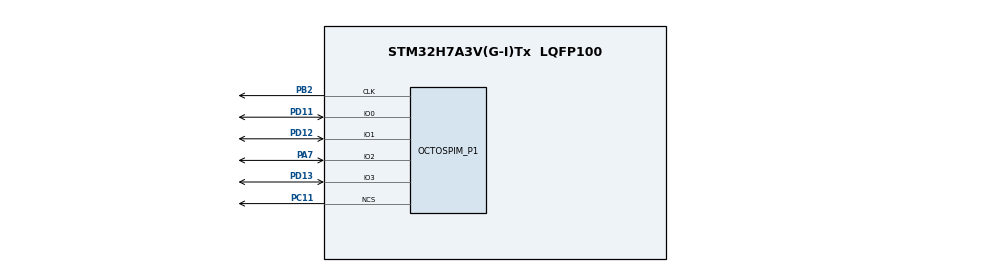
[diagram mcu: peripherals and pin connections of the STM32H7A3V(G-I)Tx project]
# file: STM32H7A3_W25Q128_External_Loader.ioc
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CORTEX_M7.AccessPermission_S-Cortex_Memory_Protection_Unit_Region1_Settings_S=MPU_REGION_FULL_ACCESS
CORTEX_M7.BaseAddress_S-Cortex_Memory_Protection_Unit_Region1_Settings_S=0x90000000
CORTEX_M7.Enable_S-Cortex_Memory_Protection_Unit_Region1_Settings_S=MPU_REGION_ENABLE
CORTEX_M7.IsCacheable_S-Cortex_Memory_Protection_Unit_Region1_Settings_S=MPU_ACCESS_CACHEABLE
CORTEX_M7.Size_S-Cortex_Memory_Protection_Unit_Region1_Settings_S=MPU_REGION_SIZE_64MB
CORTEX_M7.default_mode_Activation=1
Mcu.Family=STM32H7
Mcu.Name=STM32H7A3V(G-I)Tx
Mcu.Package=LQFP100
NVIC.PriorityGroup=NVIC_PRIORITYGROUP_4
OCTOSPI1.ChipSelectHighTime=4
OCTOSPI1.ClockPrescaler=4
OCTOSPI1.DeviceSize=24
OCTOSPI1.SampleShifting=HAL_OSPI_SAMPLE_SHIFTING_HALFCYCLE
PA13.Mode=Serial_Wire
PA13.Signal=DEBUG_JTMS-SWDIO
PA14.Mode=Serial_Wire
PA14.Signal=DEBUG_JTCK-SWCLK
PA7.Mode=OCTOSPI1_IOL_Port1L
PA7.Signal=OCTOSPIM_P1_IO2
PB2.Mode=O1_P1_CLK
PB2.Signal=OCTOSPIM_P1_CLK
PC11.Mode=OCTOSPI1_Port1_NCS
PC11.Signal=OCTOSPIM_P1_NCS
PD11.Mode=OCTOSPI1_IOL_Port1L
PD11.Signal=OCTOSPIM_P1_IO0
PD12.Mode=OCTOSPI1_IOL_Port1L
PD12.Signal=OCTOSPIM_P1_IO1
PD13.Mode=OCTOSPI1_IOL_Port1L
PD13.Signal=OCTOSPIM_P1_IO3
PH0-OSC_IN.Mode=HSE-External-Oscillator
PH0-OSC_IN.Signal=RCC_OSC_IN
PH1-OSC_OUT.Mode=HSE-External-Oscillator
PH1-OSC_OUT.Signal=RCC_OSC_OUT
ProjectManager.HeapSize=0x200
ProjectManager.StackSize=0x400
ProjectManager.TargetToolchain=STM32CubeIDE
RCC.ADCFreq_Value=280000000
RCC.APB1Freq_Value=140000000
RCC.APB2Freq_Value=140000000
RCC.APB3Freq_Value=140000000
RCC.APB4Freq_Value=140000000
RCC.CDPPRE=RCC_APB3_DIV2
RCC.CDPPRE1=RCC_APB1_DIV2
RCC.CDPPRE2=RCC_APB2_DIV2
RCC.CortexFreq_Value=280000000
RCC.DIVM1=5
RCC.DIVM2=5
RCC.DIVM3=5
RCC.DIVN1=112
RCC.DIVN2=112
RCC.DIVN3=112
RCC.HCLKFreq_Value=280000000
RCC.HSE_VALUE=25000000
RCC.PLLSourceVirtual=RCC_PLLSOURCE_HSE
RCC.SRDPPRE=RCC_APB4_DIV2
RCC.SYSCLKFreq_VALUE=280000000
RCC.SYSCLKSource=RCC_SYSCLKSOURCE_PLLCLK
RCC.USBFreq_Value=280000000
VP_MEMORYMAP_VS_MEMORYMAP.Mode=CurAppReg
VP_OCTOSPI1_VS_quad.Mode=quad_mode
board=custom

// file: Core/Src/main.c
/* USER CODE BEGIN Header */
/**
  ******************************************************************************
  * @file           : main.c
  * @brief          : Main program body
  ******************************************************************************
  * @attention
  *
  * Copyright (c) 2025 STMicroelectronics.
  * All rights reserved.
  *
  * This software is licensed under terms that can be found in the LICENSE file
  * in the root directory of this software component.
  * If no LICENSE file comes with this software, it is provided AS-IS.
  *
  ******************************************************************************
  */
/* USER CODE END Header */
#include "main.h"
#include "memorymap.h"
#include "octospi.h"
#include "gpio.h"

/* USER CODE BEGIN Includes */
#include "W25Q128.h"
#include <string.h>
/* USER CODE END Includes */

void SystemClock_Config(void);
static void MPU_Config(void);

/* USER CODE BEGIN 0 */
#define SECTORS_COUNT 100

uint8_t buffer_test[W25Q_SECTOR_SIZE];
/* USER CODE END 0 */

int main(void)
{

  /* USER CODE BEGIN 1 */
  uint32_t var = 0;
  /* USER CODE END 1 */

  /* MPU Configuration--------------------------------------------------------*/
  MPU_Config();

  /* MCU Configuration--------------------------------------------------------*/

  /* Reset of all peripherals, Initializes the Flash interface and the Systick. */
  HAL_Init();

  /* Configure the system clock */
  SystemClock_Config();

  /* Initialize all configured peripherals */
  MX_GPIO_Init();
  MX_OCTOSPI1_Init();
  /* USER CODE BEGIN 2 */
  W25Q128_OCTO_SPI_Init(&hospi1);
  for (var = 0; var < W25Q_SECTOR_SIZE; var++) {
      buffer_test[var] = (var & 0xFF);
  }
  for (var = 0; var < SECTORS_COUNT; var++) {
      if (W25Q128_OSPI_EraseSector(&hospi1, var * W25Q_SECTOR_SIZE, (var + 1) * W25Q_SECTOR_SIZE - 1) != HAL_OK) {
          while (1) {}
      }
      if (W25Q128_OSPI_Write(&hospi1, buffer_test, var * W25Q_SECTOR_SIZE, sizeof(buffer_test)) != HAL_OK) {
          while (1) {}
      }
  }
  if (W25Q128_OSPI_EnableMemoryMappedMode(&hospi1) != HAL_OK) {
      while (1) {}
  }
  for (var = 0; var < SECTORS_COUNT; var++) {
      if (memcmp(buffer_test, (uint8_t*) (0x90000000 + var * W25Q_SECTOR_SIZE), W25Q_SECTOR_SIZE) != HAL_OK) {
          while (1) {}
      }
  }
  /* USER CODE END 2 */

  /* Infinite loop */
  while (1)
  {

  }
}

void SystemClock_Config(void)
{
  RCC_OscInitTypeDef RCC_OscInitStruct = {0};
  RCC_ClkInitTypeDef RCC_ClkInitStruct = {0};

  /*AXI clock gating */
  RCC->CKGAENR = 0xFFFFFFFF;

  /** Supply configuration update enable
  */
  HAL_PWREx_ConfigSupply(PWR_LDO_SUPPLY);

  /** Configure the main internal regulator output voltage
  */
  __HAL_PWR_VOLTAGESCALING_CONFIG(PWR_REGULATOR_VOLTAGE_SCALE0);

  while(!__HAL_PWR_GET_FLAG(PWR_FLAG_VOSRDY)) {}

  /** Initializes the RCC Oscillators according to the specified parameters
  * in the RCC_OscInitTypeDef structure.
  */
  RCC_OscInitStruct.OscillatorType = RCC_OSCILLATORTYPE_HSE;
  RCC_OscInitStruct.HSEState = RCC_HSE_ON;
  RCC_OscInitStruct.PLL.PLLState = RCC_PLL_ON;
  RCC_OscInitStruct.PLL.PLLSource = RCC_PLLSOURCE_HSE;
  RCC_OscInitStruct.PLL.PLLM = 5;
  RCC_OscInitStruct.PLL.PLLN = 112;
  RCC_OscInitStruct.PLL.PLLP = 2;
  RCC_OscInitStruct.PLL.PLLQ = 2;
  RCC_OscInitStruct.PLL.PLLR = 2;
  RCC_OscInitStruct.PLL.PLLRGE = RCC_PLL1VCIRANGE_2;
  RCC_OscInitStruct.PLL.PLLVCOSEL = RCC_PLL1VCOWIDE;
  RCC_OscInitStruct.PLL.PLLFRACN = 0;
  if (HAL_RCC_OscConfig(&RCC_OscInitStruct) != HAL_OK)
  {
    Error_Handler();
  }

  /** Initializes the CPU, AHB and APB buses clocks
  */
  RCC_ClkInitStruct.ClockType = RCC_CLOCKTYPE_HCLK|RCC_CLOCKTYPE_SYSCLK
                              |RCC_CLOCKTYPE_PCLK1|RCC_CLOCKTYPE_PCLK2
                              |RCC_CLOCKTYPE_D3PCLK1|RCC_CLOCKTYPE_D1PCLK1;
  RCC_ClkInitStruct.SYSCLKSource = RCC_SYSCLKSOURCE_PLLCLK;
  RCC_ClkInitStruct.SYSCLKDivider = RCC_SYSCLK_DIV1;
  RCC_ClkInitStruct.AHBCLKDivider = RCC_HCLK_DIV1;
  RCC_ClkInitStruct.APB3CLKDivider = RCC_APB3_DIV2;
  RCC_ClkInitStruct.APB1CLKDivider = RCC_APB1_DIV2;
  RCC_ClkInitStruct.APB2CLKDivider = RCC_APB2_DIV2;
  RCC_ClkInitStruct.APB4CLKDivider = RCC_APB4_DIV2;

  if (HAL_RCC_ClockConfig(&RCC_ClkInitStruct, FLASH_LATENCY_6) != HAL_OK)
  {
    Error_Handler();
  }
}

 /* MPU Configuration */

void MPU_Config(void)
{
  MPU_Region_InitTypeDef MPU_InitStruct = {0};

  /* Disables the MPU */
  HAL_MPU_Disable();

  /** Initializes and configures the Region and the memory to be protected
  */
  MPU_InitStruct.Enable = MPU_REGION_ENABLE;
  MPU_InitStruct.Number = MPU_REGION_NUMBER0;
  MPU_InitStruct.BaseAddress = 0x0;
  MPU_InitStruct.Size = MPU_REGION_SIZE_4GB;
  MPU_InitStruct.SubRegionDisable = 0x87;
  MPU_InitStruct.TypeExtField = MPU_TEX_LEVEL0;
  MPU_InitStruct.AccessPermission = MPU_REGION_NO_ACCESS;
  MPU_InitStruct.DisableExec = MPU_INSTRUCTION_ACCESS_DISABLE;
  MPU_InitStruct.IsShareable = MPU_ACCESS_SHAREABLE;
  MPU_InitStruct.IsCacheable = MPU_ACCESS_NOT_CACHEABLE;
  MPU_InitStruct.IsBufferable = MPU_ACCESS_NOT_BUFFERABLE;

  HAL_MPU_ConfigRegion(&MPU_InitStruct);

  /** Initializes and configures the Region and the memory to be protected
  */
  MPU_InitStruct.Number = MPU_REGION_NUMBER1;
  MPU_InitStruct.BaseAddress = 0x90000000;
  MPU_InitStruct.Size = MPU_REGION_SIZE_64MB;
  MPU_InitStruct.SubRegionDisable = 0x0;
  MPU_InitStruct.AccessPermission = MPU_REGION_FULL_ACCESS;
  MPU_InitStruct.DisableExec = MPU_INSTRUCTION_ACCESS_ENABLE;
  MPU_InitStruct.IsShareable = MPU_ACCESS_NOT_SHAREABLE;
  MPU_InitStruct.IsCacheable = MPU_ACCESS_CACHEABLE;

  HAL_MPU_ConfigRegion(&MPU_InitStruct);
  /* Enables the MPU */
  HAL_MPU_Enable(MPU_PRIVILEGED_DEFAULT);

}

void Error_Handler(void)
{
  __disable_irq();
  while (1)
  {
  }
}
